# pmac_rx_secure register map
Vendor: Texas Instruments
Registers are 32-bit, read-only, reset 0x0 unless marked. A register's access mark holds for its fields unless they carry their own. Offsets are as the file gives them; [hi:lo] are bit positions; lines under a group give offsets from that group; {n}, {i} and the like mark numbered series; <NAME> marks a mode.

## pmac_rx_secure (part 3 of 3)
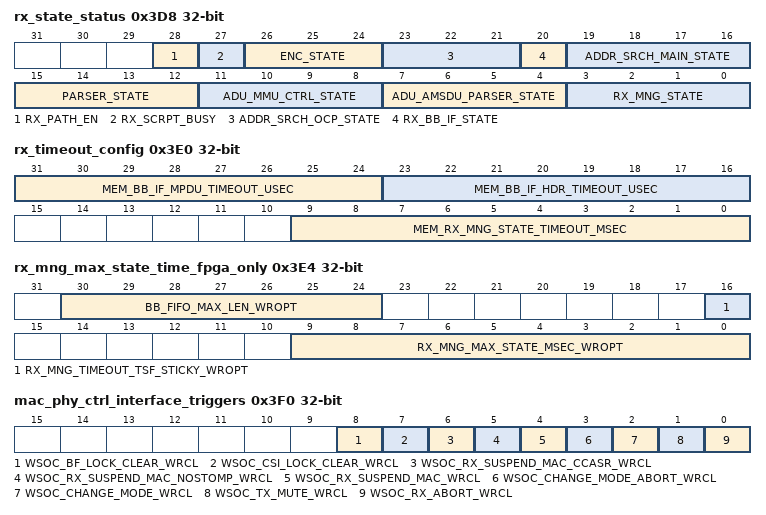
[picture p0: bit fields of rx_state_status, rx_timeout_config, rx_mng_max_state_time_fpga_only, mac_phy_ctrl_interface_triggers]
0x3D8 rx_state_status
  [28] RX_PATH_EN — state of internal rx path enable signal
  [27] RX_SCRPT_BUSY
  [26:24] ENC_STATE — 3'h0 = IDLE 3'h1 = PARSE_HDR_SEC_HDR 3'h2 = WAIT_CMD2 3'h3 = GET_KEY 3'h4 = START_ENGINE 3'h5 = ENGINE_BUSY 3'h6 = OCP_FLUSH 3'h7 = UPDATE_STS
  [23:21] ADDR_SRCH_OCP_STATE — 3'd0 = OCP_IDLE 3'd1 = RD_HASH 3'd2 = WAIT_FOR_RES 3'd3 = RD_1_FIRST 3'd4 = RD_2_FIRST 3'd5 = RD_1_NEXT 3'd6 = RD_2_NEXT 3'd7 = LAST_COMPARE
  [20] RX_BB_IF_STATE
  [19:16] ADDR_SRCH_MAIN_STATE — 3'd0 = IDLE 3'd1 = WAIT_ADDR_1 3'd2 = PROC_ADDR_1 3'd3 = WAIT_ADDR_2 3'd4 = PROC_ADDR_2 3'd5 = WAIT_ADDR_3 3'd6 = PROC_ADDR_3 3'd7 = WAIT_ADDR_4 3'd8 = PROC_ADDR_4 3'd9 = DONE
  [15:12] PARSER_STATE — 3'd0 = IDLE 3'd2 = HEADER 3'd3 = IEID 3'd4 = IELEN 3'd5 = IEINFO 3'd6 = DONE
  [11:8] ADU_MMU_CTRL_STATE — 4'd0 = WAIT_PRE_ALLOC 4'd1 = SET_ALLOC_REQ 4'd2 = WAIT_FOR_ALLOC_IRQ 4'd3 = GET_ALLOC_STATUS 4'd4 = CAPTURE_VIRT_DESC 4'd5 = NEXT_ADDR_READY 4'd6 = WAIT_FOR_LENGTH 4'd7 = SET_REALLOC_REQ 4'd8 = WAIT_FOR_REALLOC_IRQ 4'd9 = GET_REALLOC_STATUS 4'd10 = POP_DESC
  [7:4] ADU_AMSDU_PARSER_STATE — 4'd0 = PARS_IDLE 4'd1 = GET_ADDR1 4'd2 = MPDU_HDR 4'd3 = WAIT4AES 4'd4 = MSDU_SDR 4'd5 = PAYLOAD 4'd6 = FRAME_DONE 4'd7 = GET_ADDR2 4'd8 = DRAIN_SDR 4'd9 = DRAIN_MSDU 4'd10 = DRAIN_MPDU 4'd11 = MPDU_DONE
  [3:0] RX_MNG_STATE — 4'd 0 = IDLE 4'd 1 = WAIT_RX_DATA 4'd 2 = KICK_1 4'd 3 = WAIT_AES_VALID 4'd 4 = WAIT_SCR 4'd 5 = SCR_MAIN_MPDU 4'd 6 = WAIT_AMPDU 4'd 7 = SCR_FINISH_PPDU 4'd 8 = SCR_TYPE_ERROR 4'd 14 = ADU_KICK_1_EMPTY 4'd 15 = SCR_EMPTY_DESCR
0x3DC rx_scrpt_dbg_bus — internal debug bus of rx_scripter selected by mem_rx_scrpt_dbg_sel
0x3E0 rx_timeout_config access per field reset not defined
  [31:24] MEM_BB_IF_MPDU_TIMEOUT_USEC rw — timeout in usec - no data received from phy for too long time, checked during payload
  [23:16] MEM_BB_IF_HDR_TIMEOUT_USEC rw — timeout in usec - no data received from phy for too long time, checked during rx_header
  [9:0] MEM_RX_MNG_STATE_TIMEOUT_MSEC rw — timeout in msec of rx-manager state (except IDLE) is not changed for too long
0x3E4 rx_mng_max_state_time_fpga_only access per field reset not defined
  [30:24] BB_FIFO_MAX_LEN_WROPT rw — max value of bb_fifo length clear by write 0
  [16] RX_MNG_TIMEOUT_TSF_STICKY_WROPT rw — this is a sticky flag set when rx-manager-state-timeout expired, cleard on write 0 used to latch the two TSF registers (RX_MNG_STATE_CHANGE_TSF and RX_MNG_STATE_TIMEOUT_TSF) until this flag is cleared
  [9:0] RX_MNG_MAX_STATE_MSEC_WROPT rw — max value of rx-manager state timeout counter in msec clear by write 0
0x3E8 rx_mng_state_change_tsf_fpga_only
  [31:0] RX_MNG_STATE_CHANGE_TSF — keep value of TSF (usec) at RX-MANAGER state change = same time as timeout-counter-clear for extra debug info, together with RX_MNG_STATE_TIMEOUT_TSF help to estimate the STATE_TIMEOUT timeout[usec] = RX_MNG_STATE_TIMEOUT_TSF - RX_MNG_STATE_CHANGE_TSF (consider 32-bit TSF wraparound) should correlate with MEM_RX_MNG_STATE_TIMEOUT_MSEC[msec]
0x3EC rx_mng_state_timeout_tsf_fpga_only
  [31:0] RX_MNG_STATE_TIMEOUT_TSF — keep value of TSF (usec) at RX-MANAGER state timeout = same time as timeout-counter-expire for extra debug info, together with RX_MNG_STATE_CHANGE_TSF help to estimate the STATE_TIMEOUT timeout[usec] = RX_MNG_STATE_TIMEOUT_TSF - RX_MNG_STATE_CHANGE_TSF (consider 32-bit TSF wraparound) should correlate with MEM_RX_MNG_STATE_TIMEOUT_MSEC[msec]
0x3F0 mac_phy_ctrl_interface_triggers access per field
  [8] WSOC_BF_LOCK_CLEAR_WRCL wo — Pulse from PMAC to PHY indicating the BF information was already consumed, and can be cleared
  [7] WSOC_CSI_LOCK_CLEAR_WRCL wo — Pulse from PMAC to PHY indicating the CSI memory was consumed and can be cleared
  [6] WSOC_RX_SUSPEND_MAC_CCASR_WRCL wo — Suspend-CCA-Spatial-Reuse. Sideband Pulse (valid only when wsoc_rx_suspend_mac = '1').
  [5] WSOC_RX_SUSPEND_MAC_NOSTOMP_WRCL wo — Suspend-without-STOMP. Sideband Pulse (valid only when wsoc_rx_suspend_mac = '1').
  [4] WSOC_RX_SUSPEND_MAC_WRCL wo — Suspend Indication. May come with either of 2 sideband signals (rx_suspend_mac_nostomp , or rx_suspend_mac_ccasr ).
  [3] WSOC_CHANGE_MODE_ABORT_WRCL wo
  [2] WSOC_CHANGE_MODE_WRCL wo
  [1] WSOC_TX_MUTE_WRCL wo
  [0] WSOC_RX_ABORT_WRCL wo
0x3F4 mac_phy_ctrl_interface_config access per field
  [3:0] MEM_PHY_NEXT_MODE_WROPT rw
0x3F8 links_ps_state access per field
  [23:0] LINKS_PS_STATE_VAL_WROPT rw — state of the connected stations PS. bit per link. 1: STA is in PS 0: STA is active
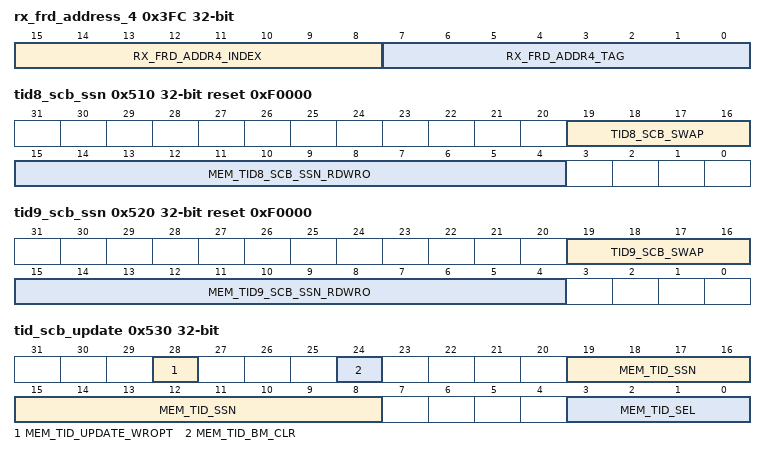
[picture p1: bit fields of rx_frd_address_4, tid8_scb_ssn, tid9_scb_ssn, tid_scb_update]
0x3FC rx_frd_address_4
  [15:8] RX_FRD_ADDR4_INDEX — Results collected from address search mechanism by the the header processing in the PMAC index field value is according to TAG field: TAG = 7 : index = 0..127 descendants TAG = 6 : index = 0..63 links TAG = 5 : index = 0..31 multicast TAG = 4 : index = 0..15 local addr TAG = 3 : index = 0..7 (reserved) TAG = 2 : index = 0..3 (reserved) else : index = 0xFF
  [7:0] RX_FRD_ADDR4_TAG — Results collected from address search mechanism by the the header processing in the PMAC TAG enumeration: 8'd 7 = DESCEND_TAG 8'd 6 = PEER_TAG 8'd 5 = MULTICAST_TAG 8'd 4 = LOCAL_TAG 8'd 3 = RESERVED_3_TAG 8'd 2 = RESERVED_2_TAG 8'd 1 = LOCAL_MESH_TAG 8'd 0 = PARENT_MESH_TAG 8'h FF = ERROR_TAG
{0x400+0x10*i} tid{i}_ba_ssn (i=0..7)
  [15:4] MEM_TID{i}_BA_SSN_RDWRO — TID{i} BA SSN. The user must read all TID{i} BA group registers SSN, BM_LSB and BM_MSB one after the other. SSN register must be read first since it locks the whole group from changing their values. BM_MSB register must be read last to release the lock.
{0x404+0x10*i} tid{i}_ba_bm_lsb (i=0..7)
  [31:0] MEM_TID{i}_BA_BM_LSB_RDWRO — TID{i} BA bitmap 32 LSB. The user must read all TID{i} BA group registers SSN, BM_LSB and BM_MSB one after the other. SSN register must be read first since it locks the whole group from changing their values. BM_MSB register must be read last to release the lock.
{0x408+0x10*i} tid{i}_ba_bm_msb (i=0..7)
  [31:0] MEM_TID{i}_BA_BM_MSB_RDWRO — TID{i} BA bitmap 32 MSB. The user must read all TID{i} BA group registers SSN, BM_LSB and BM_MSB one after the other. SSN register must be read first since it locks the whole group from changing their values. BM_MSB register must be read last to release the lock.
{0x480+0x10*i} tid{i}_scb_ssn access per field (i=0..7)
  [15:4] MEM_TID{i}_SCB_SSN_RDWRO rw — TID{i} SCB SSN
{0x484+0x10*i} tid{i}_scb_bm_lsb rw (i=0..7)
  [31:0] MEM_TID{i}_SCB_BM_LSB_RDWRO — TID{i} SCB bitmap 32 LSB
{0x488+0x10*i} tid{i}_scb_bm_msb rw (i=0..7)
  [31:0] MEM_TID{i}_SCB_BM_MSB_RDWRO — TID{i} SCB bitmap 32 MSB
0x500 tid8_ba_ssn — Scoreboard 8 has two operating modes. The mode is set by scb_mode register. 1. Regular scoreboard in single TID mode (scb_mode=0x0) 2. Dynamic fragmentation scoreboard in multi TID mode (scb_mode=0x1)
  [15:4] MEM_TID8_BA_SSN_RDWRO — TID8 BA SSN. The user must read all TID8 BA group registers SSN, BM_LSB and BM_MSB one after the other. SSN register must be read first since it locks the whole group from changing their values. BM_MSB register must be read last to release the lock.
0x504 tid8_ba_bm_lsb — Scoreboard 8 has two operating modes. The mode is set by scb_mode register. 1. Regular scoreboard in single TID mode (scb_mode=0x0) 2. Dynamic fragmentation scoreboard in multi TID mode (scb_mode=0x1)
  [31:0] MEM_TID8_BA_BM_LSB_RDWRO — TID8 BA bitmap 32 LSB. The user must read all TID8 BA group registers SSN, BM_LSB and BM_MSB one after the other. SSN register must be read first since it locks the whole group from changing their values. BM_MSB register must be read last to release the lock.
0x508 tid8_ba_bm_msb — Scoreboard 8 has two operating modes. The mode is set by scb_mode register. 1. Regular scoreboard in single TID mode (scb_mode=0x0) 2. Dynamic fragmentation scoreboard in multi TID mode (scb_mode=0x1)
  [31:0] MEM_TID8_BA_BM_MSB_RDWRO — TID8 BA bitmap 32 MSB. The user must read all TID8 BA group registers SSN, BM_LSB and BM_MSB one after the other. SSN register must be read first since it locks the whole group from changing their values. BM_MSB register must be read last to release the lock.
0x510 tid8_scb_ssn reset 0xF0000 — Scoreboard 8 has two operating modes. The mode is set by scb_mode register. 1. Regular scoreboard in single TID mode (scb_mode=0x0) 2. Dynamic fragmentation scoreboard in multi TID mode (scb_mode=0x1)
  [19:16] TID8_SCB_SWAP — Indicates which TID holds TID8 SCB for dynamic fragmentation
  [15:4] MEM_TID8_SCB_SSN_RDWRO — TID8 SCB SSN. TID8 is used for dynamic fragmentation
0x514 tid8_scb_bm_lsb — Scoreboard 8 has two operating modes. The mode is set by scb_mode register. 1. Regular scoreboard in single TID mode (scb_mode=0x0) 2. Dynamic fragmentation scoreboard in multi TID mode (scb_mode=0x1)
  [31:0] MEM_TID8_SCB_BM_LSB_RDWRO — TID8 SCB bitmap 32 LSB. TID8 is used for dynamic fragmentation
0x518 tid8_scb_bm_msb — Scoreboard 8 has two operating modes. The mode is set by scb_mode register. 1. Regular scoreboard in single TID mode (scb_mode=0x0) 2. Dynamic fragmentation scoreboard in multi TID mode (scb_mode=0x1)
  [31:0] MEM_TID8_SCB_BM_MSB_RDWRO — TID8 SCB bitmap 32 MSB. TID8 is used for dynamic fragmentation
0x520 tid9_scb_ssn reset 0xF0000
  [19:16] TID9_SCB_SWAP — Indicates which TID holds TID9 SCB for dynamic fragmentation
  [15:4] MEM_TID9_SCB_SSN_RDWRO — TID9 SCB SSN. TID9 is used for dynamic fragmentation
0x524 tid9_scb_bm_lsb
  [31:0] MEM_TID9_SCB_BM_LSB_RDWRO — TID9 SCB bitmap 32 LSB. TID9 is used for dynamic fragmentation
0x528 tid9_scb_bm_msb
  [31:0] MEM_TID9_SCB_BM_MSB_RDWRO — TID9 SCB bitmap 32 MSB. TID9 is used for dynamic fragmentation
0x530 tid_scb_update access per field — In PBAA (Protected block ack agreement) the SW use this register to select and update one TID scoreboard at a time. The SW must check that the MEM_TID_UPDATE_WROPT field value is 0x0 before submitting another request for TID scoreboard update.
  [28] MEM_TID_UPDATE_WROPT rw — Submit update request for the selected TID. The field will be cleared automatically after request completion. 0x0: Request completed 0x1: Submit Request / Request in progress
  [24] MEM_TID_BM_CLR rw — Clear the bitmap of the selected TID (64 bits)
  [19:8] MEM_TID_SSN rw — Set new SSN to the selected TID
  [3:0] MEM_TID_SEL rw — Select which TID scoreboard to update
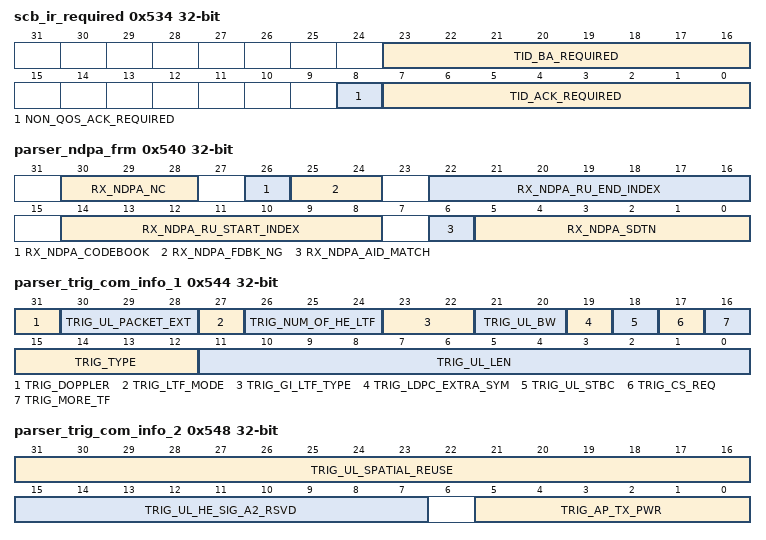
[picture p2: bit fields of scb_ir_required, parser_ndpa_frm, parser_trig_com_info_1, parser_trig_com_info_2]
0x534 scb_ir_required — Hold the status of the Immediate Response (IR) required
  [23:16] TID_BA_REQUIRED — Indicates which TID required BA response. One bit per TID. [0]: TID0 [1]: TID1 [2]: TID2 [3]: TID3 [4]: TID4 [5]: TID5 [6]: TID6 [7]: TID7
  [8] NON_QOS_ACK_REQUIRED — Indicates if non QOS packet required ACK response
  [7:0] TID_ACK_REQUIRED — Indicates which TID required ACK response. One bit per TID. [0]: TID0 [1]: TID1 [2]: TID2 [3]: TID3 [4]: TID4 [5]: TID5 [6]: TID6 [7]: TID7
0x538 scb_bar_ssn_bypass access per field — Bypass BAR SSN checker
  [0] MEM_BAR_SSN_BYPASS rw — Bypass BAR SSN checker STATIC configuration, not expected to change while receiving packets
0x540 parser_ndpa_frm
  [30:28] RX_NDPA_NC, [26] RX_NDPA_CODEBOOK, [25:24] RX_NDPA_FDBK_NG, [22:16] RX_NDPA_RU_END_INDEX, [14:8] RX_NDPA_RU_START_INDEX, [6] RX_NDPA_AID_MATCH, [5:0] RX_NDPA_SDTN
0x544 parser_trig_com_info_1
  [31] TRIG_DOPPLER, [30:28] TRIG_UL_PACKET_EXT, [27] TRIG_LTF_MODE, [26:24] TRIG_NUM_OF_HE_LTF, [23:22] TRIG_GI_LTF_TYPE, [21:20] TRIG_UL_BW, [19] TRIG_LDPC_EXTRA_SYM, [18] TRIG_UL_STBC, [17] TRIG_CS_REQ, [16] TRIG_MORE_TF, [15:12] TRIG_TYPE, [11:0] TRIG_UL_LEN
0x548 parser_trig_com_info_2
  [31:16] TRIG_UL_SPATIAL_REUSE, [15:7] TRIG_UL_HE_SIG_A2_RSVD, [5:0] TRIG_AP_TX_PWR
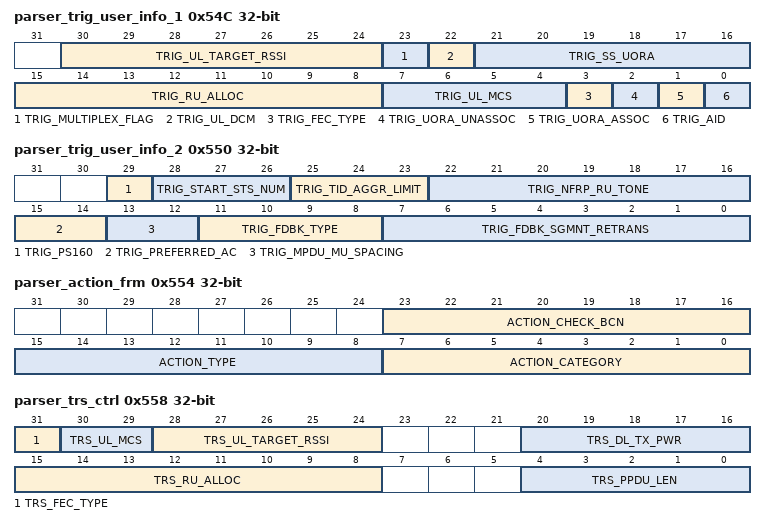
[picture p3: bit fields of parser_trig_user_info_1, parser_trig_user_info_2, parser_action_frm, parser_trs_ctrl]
0x54C parser_trig_user_info_1
  [30:24] TRIG_UL_TARGET_RSSI, [23] TRIG_MULTIPLEX_FLAG, [22] TRIG_UL_DCM, [21:16] TRIG_SS_UORA, [15:8] TRIG_RU_ALLOC, [7:4] TRIG_UL_MCS, [3] TRIG_FEC_TYPE, [2] TRIG_UORA_UNASSOC, [1] TRIG_UORA_ASSOC, [0] TRIG_AID
0x550 parser_trig_user_info_2
  [29] TRIG_PS160, [28:26] TRIG_START_STS_NUM, [25:23] TRIG_TID_AGGR_LIMIT, [22:16] TRIG_NFRP_RU_TONE, [15:14] TRIG_PREFERRED_AC, [13:12] TRIG_MPDU_MU_SPACING, [11:8] TRIG_FDBK_TYPE, [7:0] TRIG_FDBK_SGMNT_RETRANS
0x554 parser_action_frm
  [23:16] ACTION_CHECK_BCN, [15:8] ACTION_TYPE, [7:0] ACTION_CATEGORY
0x558 parser_trs_ctrl
  [31] TRS_FEC_TYPE, [30:29] TRS_UL_MCS, [28:24] TRS_UL_TARGET_RSSI, [20:16] TRS_DL_TX_PWR, [15:8] TRS_RU_ALLOC, [4:0] TRS_PPDU_LEN
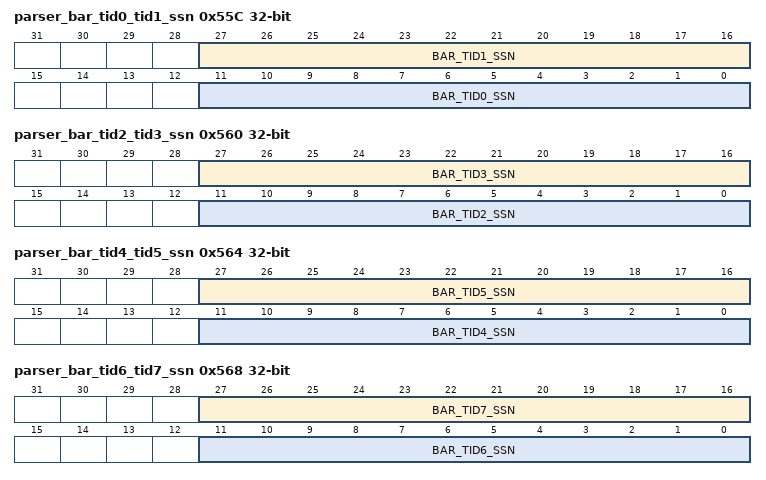
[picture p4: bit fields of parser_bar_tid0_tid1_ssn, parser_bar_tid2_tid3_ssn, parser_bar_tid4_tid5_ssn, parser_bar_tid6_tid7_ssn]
0x55C parser_bar_tid0_tid1_ssn
  [27:16] BAR_TID1_SSN, [11:0] BAR_TID0_SSN
0x560 parser_bar_tid2_tid3_ssn
  [27:16] BAR_TID3_SSN, [11:0] BAR_TID2_SSN
0x564 parser_bar_tid4_tid5_ssn
  [27:16] BAR_TID5_SSN, [11:0] BAR_TID4_SSN
0x568 parser_bar_tid6_tid7_ssn
  [27:16] BAR_TID7_SSN, [11:0] BAR_TID6_SSN
0x56C parser_sec_hdr
  [7:0] SEC_HDR_KEY_ID
0x570 rx_if_bb_rx_last_ovr access per field
  [0] MEM_RX_IF_BB_TIMEOUT_RX_LAST_OVR_EN rw — Enable this bit in order to force rx_last upon rx_bb_if timeout.
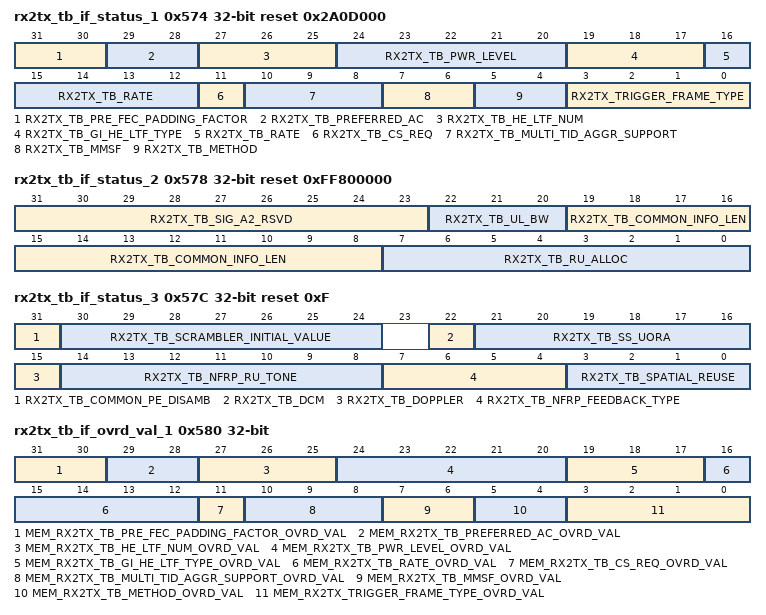
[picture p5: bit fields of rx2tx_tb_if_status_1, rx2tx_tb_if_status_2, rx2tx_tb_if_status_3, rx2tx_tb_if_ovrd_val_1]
0x574 rx2tx_tb_if_status_1 reset 0x2A0D000 — RX2TX TB fields status
  [31:30] RX2TX_TB_PRE_FEC_PADDING_FACTOR, [29:28] RX2TX_TB_PREFERRED_AC, [27:25] RX2TX_TB_HE_LTF_NUM, [24:20] RX2TX_TB_PWR_LEVEL, [19:17] RX2TX_TB_GI_HE_LTF_TYPE, [16:12] RX2TX_TB_RATE, [11] RX2TX_TB_CS_REQ, [10:8] RX2TX_TB_MULTI_TID_AGGR_SUPPORT, [7:6] RX2TX_TB_MMSF, [5:4] RX2TX_TB_METHOD, [3:0] RX2TX_TRIGGER_FRAME_TYPE
0x578 rx2tx_tb_if_status_2 reset 0xFF800000 — RX2TX TB fields status
  [31:23] RX2TX_TB_SIG_A2_RSVD, [22:20] RX2TX_TB_UL_BW, [19:8] RX2TX_TB_COMMON_INFO_LEN, [7:0] RX2TX_TB_RU_ALLOC
0x57C rx2tx_tb_if_status_3 reset 0xF — RX2TX TB fields status
  [31] RX2TX_TB_COMMON_PE_DISAMB, [30:24] RX2TX_TB_SCRAMBLER_INITIAL_VALUE, [22] RX2TX_TB_DCM, [21:16] RX2TX_TB_SS_UORA, [15] RX2TX_TB_DOPPLER, [14:8] RX2TX_TB_NFRP_RU_TONE, [7:4] RX2TX_TB_NFRP_FEEDBACK_TYPE, [3:0] RX2TX_TB_SPATIAL_REUSE
0x580 rx2tx_tb_if_ovrd_val_1 rw — RX2TX TB fields override value
  [31:30] MEM_RX2TX_TB_PRE_FEC_PADDING_FACTOR_OVRD_VAL, [29:28] MEM_RX2TX_TB_PREFERRED_AC_OVRD_VAL, [27:25] MEM_RX2TX_TB_HE_LTF_NUM_OVRD_VAL, [24:20] MEM_RX2TX_TB_PWR_LEVEL_OVRD_VAL, [19:17] MEM_RX2TX_TB_GI_HE_LTF_TYPE_OVRD_VAL, [16:12] MEM_RX2TX_TB_RATE_OVRD_VAL, [11] MEM_RX2TX_TB_CS_REQ_OVRD_VAL, [10:8] MEM_RX2TX_TB_MULTI_TID_AGGR_SUPPORT_OVRD_VAL, [7:6] MEM_RX2TX_TB_MMSF_OVRD_VAL, [5:4] MEM_RX2TX_TB_METHOD_OVRD_VAL, [3:0] MEM_RX2TX_TRIGGER_FRAME_TYPE_OVRD_VAL
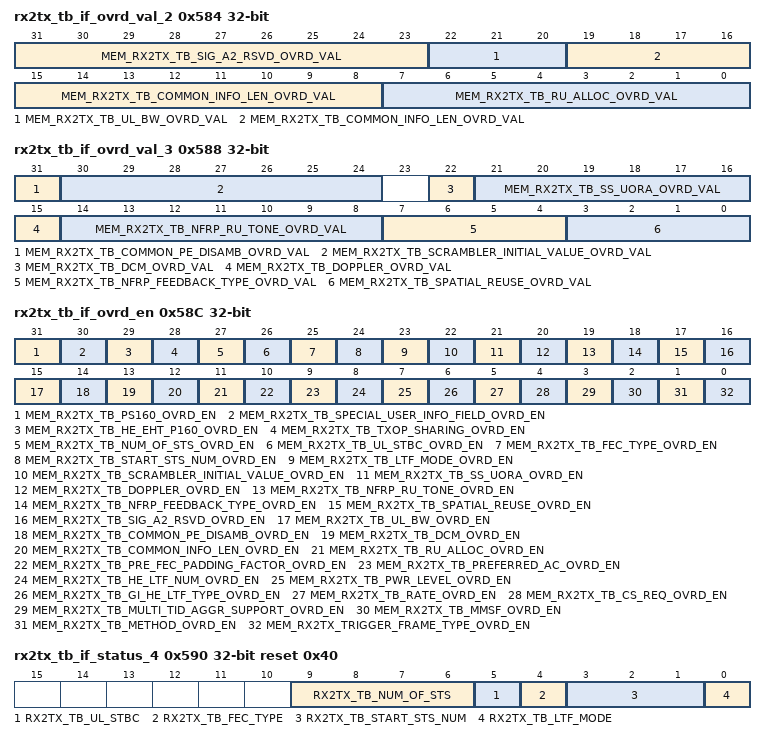
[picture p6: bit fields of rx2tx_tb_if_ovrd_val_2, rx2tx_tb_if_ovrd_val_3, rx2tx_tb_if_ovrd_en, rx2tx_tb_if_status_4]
0x584 rx2tx_tb_if_ovrd_val_2 rw — RX2TX TB fields override value
  [31:23] MEM_RX2TX_TB_SIG_A2_RSVD_OVRD_VAL, [22:20] MEM_RX2TX_TB_UL_BW_OVRD_VAL, [19:8] MEM_RX2TX_TB_COMMON_INFO_LEN_OVRD_VAL, [7:0] MEM_RX2TX_TB_RU_ALLOC_OVRD_VAL
0x588 rx2tx_tb_if_ovrd_val_3 access per field — RX2TX TB fields override value
  [31] MEM_RX2TX_TB_COMMON_PE_DISAMB_OVRD_VAL rw, [30:24] MEM_RX2TX_TB_SCRAMBLER_INITIAL_VALUE_OVRD_VAL rw, [22] MEM_RX2TX_TB_DCM_OVRD_VAL rw, [21:16] MEM_RX2TX_TB_SS_UORA_OVRD_VAL rw, [15] MEM_RX2TX_TB_DOPPLER_OVRD_VAL rw, [14:8] MEM_RX2TX_TB_NFRP_RU_TONE_OVRD_VAL rw, [7:4] MEM_RX2TX_TB_NFRP_FEEDBACK_TYPE_OVRD_VAL rw, [3:0] MEM_RX2TX_TB_SPATIAL_REUSE_OVRD_VAL rw
0x58C rx2tx_tb_if_ovrd_en rw — RX2TX TB fields override enable
  [31] MEM_RX2TX_TB_PS160_OVRD_EN, [30] MEM_RX2TX_TB_SPECIAL_USER_INFO_FIELD_OVRD_EN, [29] MEM_RX2TX_TB_HE_EHT_P160_OVRD_EN, [28] MEM_RX2TX_TB_TXOP_SHARING_OVRD_EN, [27] MEM_RX2TX_TB_NUM_OF_STS_OVRD_EN, [26] MEM_RX2TX_TB_UL_STBC_OVRD_EN, [25] MEM_RX2TX_TB_FEC_TYPE_OVRD_EN, [24] MEM_RX2TX_TB_START_STS_NUM_OVRD_EN, [23] MEM_RX2TX_TB_LTF_MODE_OVRD_EN, [22] MEM_RX2TX_TB_SCRAMBLER_INITIAL_VALUE_OVRD_EN, [21] MEM_RX2TX_TB_SS_UORA_OVRD_EN, [20] MEM_RX2TX_TB_DOPPLER_OVRD_EN, [19] MEM_RX2TX_TB_NFRP_RU_TONE_OVRD_EN, [18] MEM_RX2TX_TB_NFRP_FEEDBACK_TYPE_OVRD_EN, [17] MEM_RX2TX_TB_SPATIAL_REUSE_OVRD_EN, [16] MEM_RX2TX_TB_SIG_A2_RSVD_OVRD_EN, [15] MEM_RX2TX_TB_UL_BW_OVRD_EN, [14] MEM_RX2TX_TB_COMMON_PE_DISAMB_OVRD_EN, [13] MEM_RX2TX_TB_DCM_OVRD_EN, [12] MEM_RX2TX_TB_COMMON_INFO_LEN_OVRD_EN, [11] MEM_RX2TX_TB_RU_ALLOC_OVRD_EN, [10] MEM_RX2TX_TB_PRE_FEC_PADDING_FACTOR_OVRD_EN, [9] MEM_RX2TX_TB_PREFERRED_AC_OVRD_EN, [8] MEM_RX2TX_TB_HE_LTF_NUM_OVRD_EN, [7] MEM_RX2TX_TB_PWR_LEVEL_OVRD_EN, [6] MEM_RX2TX_TB_GI_HE_LTF_TYPE_OVRD_EN, [5] MEM_RX2TX_TB_RATE_OVRD_EN, [4] MEM_RX2TX_TB_CS_REQ_OVRD_EN, [3] MEM_RX2TX_TB_MULTI_TID_AGGR_SUPPORT_OVRD_EN, [2] MEM_RX2TX_TB_MMSF_OVRD_EN, [1] MEM_RX2TX_TB_METHOD_OVRD_EN, [0] MEM_RX2TX_TRIGGER_FRAME_TYPE_OVRD_EN
0x590 rx2tx_tb_if_status_4 reset 0x40 — RX2TX TB fields status
  [9:6] RX2TX_TB_NUM_OF_STS, [5] RX2TX_TB_UL_STBC, [4] RX2TX_TB_FEC_TYPE, [3:1] RX2TX_TB_START_STS_NUM, [0] RX2TX_TB_LTF_MODE
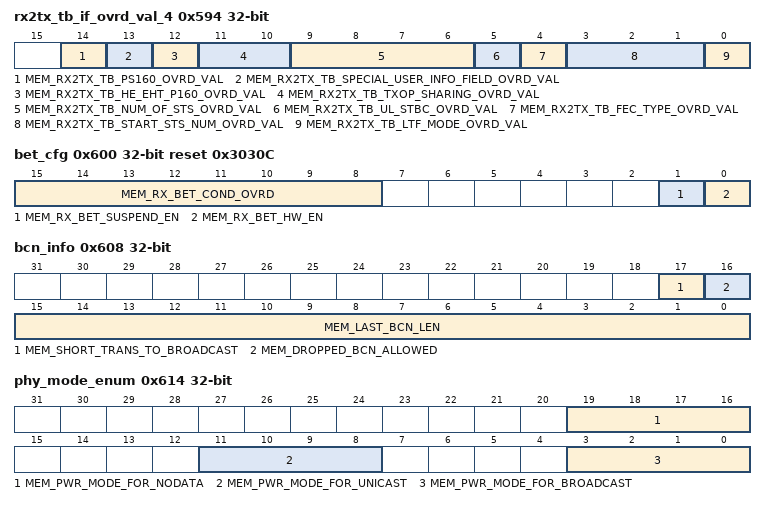
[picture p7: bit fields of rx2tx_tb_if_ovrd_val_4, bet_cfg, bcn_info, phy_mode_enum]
0x594 rx2tx_tb_if_ovrd_val_4 access per field — RX2TX TB fields override value
  [14] MEM_RX2TX_TB_PS160_OVRD_VAL rw, [13] MEM_RX2TX_TB_SPECIAL_USER_INFO_FIELD_OVRD_VAL rw, [12] MEM_RX2TX_TB_HE_EHT_P160_OVRD_VAL rw, [11:10] MEM_RX2TX_TB_TXOP_SHARING_OVRD_VAL rw, [9:6] MEM_RX2TX_TB_NUM_OF_STS_OVRD_VAL rw, [5] MEM_RX2TX_TB_UL_STBC_OVRD_VAL rw, [4] MEM_RX2TX_TB_FEC_TYPE_OVRD_VAL rw, [3:1] MEM_RX2TX_TB_START_STS_NUM_OVRD_VAL rw, [0] MEM_RX2TX_TB_LTF_MODE_OVRD_VAL rw
0x600 bet_cfg access per field reset 0x3030C (reset mask 0xFFFFFFFC) — Beacon Early Termination - Module configuration
  [15:8] MEM_RX_BET_COND_OVRD rw — Override bits to ignore each of the conditions for termination decision: '1' - to override the condition, which means - beacon can be terminated regardless of the specific condition: bit-0 for: Frame is beacon bit-1 for: Frame in our BSS bit-2 for: Beacon Length matches the previous ones bit-3 for: Counter of previous dropped beacons - if reaches a THR number do not terminate bit-4 for: Reasonable timestamp - STA and AP are aligned on TSF
  [1] MEM_RX_BET_SUSPEND_EN rw — Configurable reg to enable BET module to Suspend '1' - Enable (default) '0' - Disable
  [0] MEM_RX_BET_HW_EN rw — Configurable reg to Enable/Disable all BET decisions outputs (Abort/Suspend/Change-Mode) '1' - Enable (default) '0' - Disable
0x604 bet_db_proc_done access per field reset 0x3 — Enable indication from scripter for BET module
  [0] MEM_RX_BET_DB_PROC_DONE rw — Indication that all relevant information for the BET module was downloaded and valid. Default is '1', but if scripter wants to hold the final decision until relevant data is downloaded, it writes '0' to this bit at the beginning of the first script, and when data was downloaded then it writes back '1', which enables the BET module to output the final decisions when ready.
0x608 bcn_info access per field reset not defined — Beacon information for BET conditions
  [17] MEM_SHORT_TRANS_TO_BROADCAST rw — Configurable reg to tell if PHY mode transition is short enough, so broadcast frames can be sent right after beacon reception is completed (SIFS + AIFS). '0' - Abort will be recommended if broadcast change mode is required (to 'RX-Only or Normal) '1' - Complete beacon reception in this case (or suspend if it fits the conditions)
  [16] MEM_DROPPED_BCN_ALLOWED rw — SW recommendation to avoid termination of current beacon (for condition #4 ('mem_rx_bet_cond_ovrd':bit-3)). Change mode or abort (for broadcast change mode) can still take place.
  [15:0] MEM_LAST_BCN_LEN rw — Last beacon length fully delivered to SW (for condition #3 ('mem_rx_bet_cond_ovrd':bit-2)). (beacon length == PLCP length minus the TIM IE that may vary)
0x60C timestamp_thr access per field reset 0x1FC1FC00 — Timestamp Thershold
  [16:5] MEM_TSF_MAX_GAP_BITMASK rw — Bit-Mask configuration to check the difference between expected AP-TSF (mem_expected_bcn_timestamp) and the AP-Timestamp field from the received beacon. This register represents which of the lsb bits to mask, for example If this register is set to 0x007F - it means compare only the 20 msbits and ignore the 12 lsb. In order to save bits when comparing the minimum number of bits to mask will be 5 (meaning resolution is 32uSec). Reg-val Actual mask time resolution [16:5] [31:0] Mask [us] ------- --------- ---------------- 000 0000_001F 32 001 0000_003F 64 003 0000_007F 128 007 0000_00FF 256 00F 0000_01FF 512 01F 0000_03FF 1024 03F 0000_07FF 2048 07F 0000_0FFF 4096 0FF 0000_1FFF 8192 1FF 0000_3FFF 16384 3FF 0000_7FFF 32768 7FF 0000_FFFF 65536 FFF 0001_FFFF 131072 (~130mSec of difference ignore)
0x610 expected_timestamp access per field — Calculated Station Timestamp
  [31:5] MEM_EXPECTED_BCN_TIMESTAMP rw — [31:5] - SW calculated TSF for expected timestamp in the coming beacon - resolution is 32uSec [31:5]
0x614 phy_mode_enum access per field reset not defined — PHY Power Mode Enumeration
  [19:16] MEM_PWR_MODE_FOR_NODATA rw — Configurable reg reflects required pwr-mode for No-Data (Default 'Prepare-to-Sleep')
  [11:8] MEM_PWR_MODE_FOR_UNICAST rw — Configurable reg reflects required pwr-mode for Unicast (Default 'Normal')
  [3:0] MEM_PWR_MODE_FOR_BROADCAST rw — Configurable reg reflects required pwr-mode for Broadcast (Default 'RX-Only')
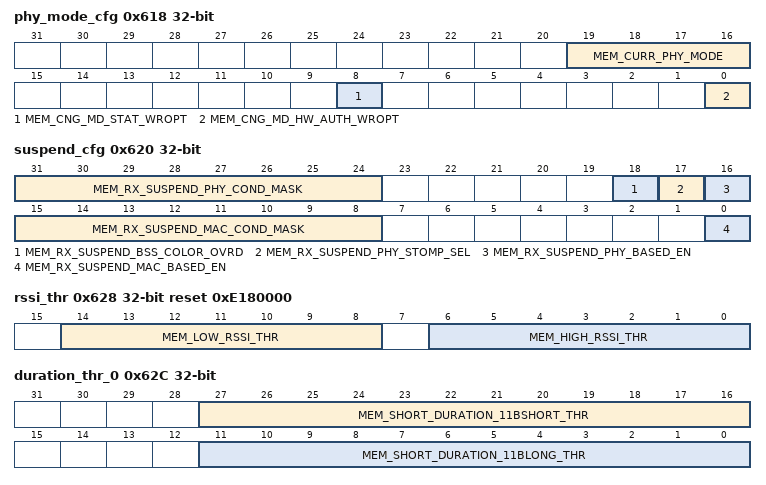
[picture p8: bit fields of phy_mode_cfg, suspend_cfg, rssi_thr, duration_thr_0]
0x618 phy_mode_cfg access per field reset not defined — PMAC authority handshake and current PHY-Mode
  [19:16] MEM_CURR_PHY_MODE rw — SW configuration of current PHY power mode: 0- Normal 1- RX-Only 2- Listen 3- Off 4- LPDS 5- Idle 6- Standby 7- Prepared to sleep
  [8] MEM_CNG_MD_STAT_WROPT rw — Status bit to tell SW if HW issued change-mode request '1' - Change mode command sent by HW, in this case HW also clear 'Authority' bit, so HW can not send another change-mode command
  [0] MEM_CNG_MD_HW_AUTH_WROPT rw — SW gives the 'Authority' to either HW of SW, to issue change-mode request if needed: '0' - Only SW is allowed to change mode '1' - Only HW is allowed to change mode SW may take the 'Authority' back by clearing this bit
0x620 suspend_cfg access per field reset not defined — RX-Suspend - Module configuration
  [31:24] MEM_RX_SUSPEND_PHY_COND_MASK rw — Mask bit for each of the PHY based conditions. '1' - disable this condition, which means, suspend will not be issued for this specific condition: bit-0 for: [HE] - MultiUser downlink that doesn't include us bit-1 for: [HE] - Uplink frame in our BSS bit-2 for: [HE] - Downlink with unsupported rate (bss color match) bit-3 for: [HE] - TB uplink frame in our BSS bit-4 for: [HE] - Unsupported rate (bssid unknown)
  [18] MEM_RX_SUSPEND_BSS_COLOR_OVRD rw — Override bssid match condition for the PHY-based suspension decision
  [17] MEM_RX_SUSPEND_PHY_STOMP_SEL rw — Select if frames suspension based on PHY-Header are W/Stomp ('1') or WO/Stomp ('0'-default)
  [16] MEM_RX_SUSPEND_PHY_BASED_EN rw — Configurable reg to Enable/Disable AX/AC frame Suspension decisions outputs, based on PHY-Header '1' - Enable (default) '0' - Disable
  [15:8] MEM_RX_SUSPEND_MAC_COND_MASK rw — Mask bit for each of the MAC based conditions. '1' - disable this condition, which means, suspend will not be issued for this specific condition: bit-0 for: Frame is not in our BSS bit-1 for: Unicast data not to us bit-2 for: Long data broadcast bit-3 for: Multicast data not to us bit-4 for: [HE] - No more valid data in current aggregation
  [0] MEM_RX_SUSPEND_MAC_BASED_EN rw — Configurable reg to Enable/Disable Frame Suspension decisions outputs, based on MAC-Header: '1' - Enable (default) '0' - Disable
0x624 suspend_db_proc_done access per field reset 0x3 — Enable indication from scripter for Suspend module
  [0] MEM_RX_SUSPEND_DB_PROC_DONE rw — Indication that all relevant information for the SUSPEND module was downloaded and valid. Default is '1', but if scripter wants to hold the final decision until relevant data is downloaded, it writes '0' to this bit at the beginning of the first script, and when data was downloaded then it writes back '1', which enables the BET module to output the final decisions when ready.
0x628 rssi_thr access per field reset 0xE180000 (reset mask 0xFFFF8000) — RSSI Threshold
  [14:8] MEM_LOW_RSSI_THR rw — Configurable Threshold for Low RSSI ('rx_rssi') - (0= -110dBm, 127= 17dBm) Below this threshold RSSI is low - it allows Suspend with Spatial-Reuse
  [6:0] MEM_HIGH_RSSI_THR rw — Configurable Threshold for High RSSI ('rx_rssi') - (0= -110dBm, 127= 17dBm) Above this threshold suspend w/stomp is 'upgraded' to suspend no/stomp
0x62C duration_thr_0 access per field reset not defined — Duration Threshold
  [27:16] MEM_SHORT_DURATION_11BSHORT_THR rw — For 11B-SHORT frame format - Threshold set for short 'rx_duration_id' Some frame should be suspended in case the duration field is not higher than SIFS & ack protection
  [11:0] MEM_SHORT_DURATION_11BLONG_THR rw — For 11B-LONG frame format - Threshold set for short 'rx_duration_id' Some frame should be suspended in case the duration field is not higher than SIFS & ack protection
0x630 duration_thr_1 access per field reset 0x78078 — Duration Threshold
  [11:0] MEM_SHORT_DURATION_NON11B_THR rw — For non-11B frame format (ofdm, 11n, 11ax etc) - Threshold set for short 'rx_duration_id' Some frame should be suspended in case the duration field is not higher than SIFS & ack protection
0x634 bdcst_len_thr access per field reset 0x50050 — Broadcast Length Threshold
  [11:0] MEM_LONG_BDCST_LEN_THR rw — Threshold set for Long Broadcast Length. Suspend may occure on Long data broadcast.
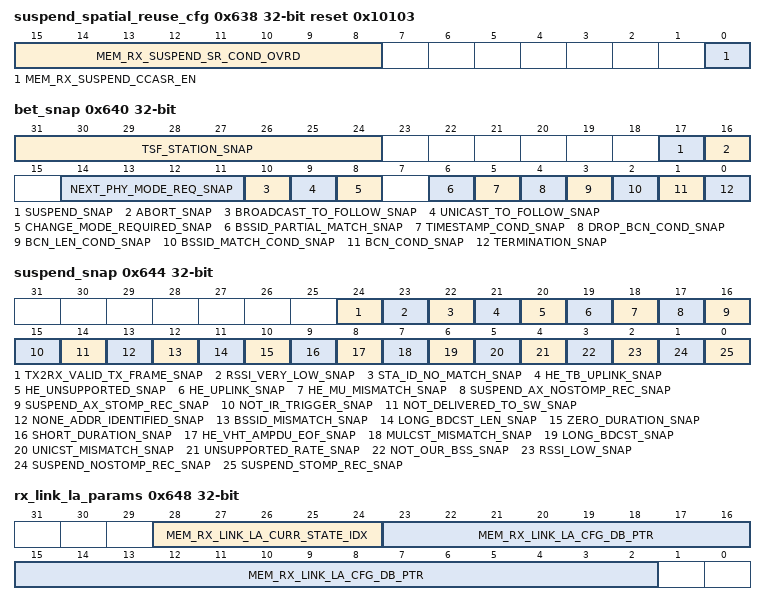
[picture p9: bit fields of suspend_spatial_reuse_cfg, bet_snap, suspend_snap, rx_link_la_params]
0x638 suspend_spatial_reuse_cfg access per field reset 0x10103 — RX-Suspend Spatial-Reuse - Feature configuration
  [15:8] MEM_RX_SUSPEND_SR_COND_OVRD rw — Override bits to ignore each of the conditions for Spatial-Reuse decision: '1' - to override the condition, which means - Spatial-Reuse can be recommended regardless of the specific condition: bit-0 for: There is a frame ready to transmit bit-1 for: Inter BSS - belongs to overlap BSS (not-our-BSS) bit-2 for: MAC address is not identified bit-3 for: Frame will not be forward to SW bit-4 for: Frame does not require Immediate-Resp
  [0] MEM_RX_SUSPEND_CCASR_EN rw — Configurable reg to Enable/Disable Frame Suspension with Spatial-Reuse (SR - CCA clear), based on MAC-Header: '1' - Enable (default) '0' - Disable
0x640 bet_snap — Snapshot of BET module
  [31:24] TSF_STATION_SNAP — Snap condition prior to BET decision - at 'bet_decision_stb' 8 bits of the received Timestamp received from the beacon: Represent bits 5 to 12 - AP-TSF[12:5] (bits 0-4 are masked anyway)
  [17] SUSPEND_SNAP — Snap condition prior to BET decision - at 'bet_decision_stb' Suspend is the BET decision recommendation
  [16] ABORT_SNAP — Snap condition prior to BET decision - at 'bet_decision_stb' Abort is the BET decision recommendation
  [14:11] NEXT_PHY_MODE_REQ_SNAP — Snap condition prior to BET decision - at 'bet_decision_stb' Target PHY-Mode (Unicast, Broadcast or None)
  [10] BROADCAST_TO_FOLLOW_SNAP — Snap condition prior to BET decision - at 'bet_decision_stb' There is a match for broadcast in the TIM element
  [9] UNICAST_TO_FOLLOW_SNAP — Snap condition prior to BET decision - at 'bet_decision_stb' There is a match for unicast in the TIM element
  [8] CHANGE_MODE_REQUIRED_SNAP — Snap condition prior to BET decision - at 'bet_decision_stb' Set if Current-PHY-Mode is different from the required target PHY-Mode, and if SW authorized this change mode in this received beacon frame.
  [6] BSSID_PARTIAL_MATCH_SNAP — Snap condition prior to BET decision - at 'bet_decision_stb' Frame in our BSS (due to 'bssid_partial_match' only. For case of 'bssid_match' see different snap - 'bssid_match_cond_snap')
  [5] TIMESTAMP_COND_SNAP — Snap condition prior to BET decision - at 'bet_decision_stb' reasonable_timestamp - The expected timestamp (configured by SW - 'mem_expected_bcn_timestamp') is in the expected range ('mem_tsf_max_gap_bitmask')
  [4] DROP_BCN_COND_SNAP — Snap condition prior to BET decision - at 'bet_decision_stb' Dropped counter allows to terminate - set by SW
  [3] BCN_LEN_COND_SNAP — Snap condition prior to BET decision - at 'bet_decision_stb' Beacon Length match the previous ones
  [2] BSSID_MATCH_COND_SNAP — Snap condition prior to BET decision - at 'bet_decision_stb' Frame in our BSS (due to 'bssid_match' only. For case of 'bssid_partial_match' see different snap - 'bssid_partial_match_snap')
  [1] BCN_COND_SNAP — Snap condition prior to BET decision - at 'bet_decision_stb' Frame is beacon
  [0] TERMINATION_SNAP — Snap condition prior to BET decision - at 'bet_decision_stb' Decision made on the received beacon, based on the relevant conditions
0x644 suspend_snap — Snapshot of SUSPEND module
  [24] TX2RX_VALID_TX_FRAME_SNAP — Snap condition of Early-Suspend decision - at 'phy_decision_stb' There is a frame ready to transmit (TX) - it allows Suspend with Spatial-Reuse
  [23] RSSI_VERY_LOW_SNAP — Snap condition of Early-Suspend decision - at 'phy_decision_stb' Received RSSI is lower than the configurable THR (rx_rssi < mem_low_rssi_thr (-82dBm)) If this received RSSI crosses this configurable THR - it allows Suspend with Spatial-Reuse
  [22] STA_ID_NO_MATCH_SNAP — Snap condition of Early-Suspend decision - at 'phy_decision_stb' (rx_sta_id_list == 3'b0) ; //(0-STA_ID_LIST_NOT_FOUND)
  [21] HE_TB_UPLINK_SNAP — Snap condition of Early-Suspend decision - at 'phy_decision_stb' TB uplink frame in our BSS
  [20] HE_UNSUPPORTED_SNAP — Snap condition of Early-Suspend decision - at 'phy_decision_stb' Downlink with unsupported rate
  [19] HE_UPLINK_SNAP — Snap condition of Early-Suspend decision - at 'phy_decision_stb' Uplink frame in our BSS
  [18] HE_MU_MISMATCH_SNAP — Snap condition of Early-Suspend decision - at 'phy_decision_stb' MultiUser downlink that doesn't include us
  [17] SUSPEND_AX_NOSTOMP_REC_SNAP — Snap condition of Early-Suspend decision - at 'phy_decision_stb' Recommendation of (AX-)Suspend, based on 'he_mu_mismatch', 'he_uplink', 'he_unsupported' and 'he_tb_uplink'
  [16] SUSPEND_AX_STOMP_REC_SNAP — Snap condition of Early-Suspend decision - at 'phy_decision_stb' Recommendation of Suspend (W/Stomp) based on 'not_our_bss' and 'unsupported_rate'
  [15] NOT_IR_TRIGGER_SNAP — Snap condition of Late-Suspend decision - at 'mac_decision_stb' Frame does not requires immediate response - it allows Suspend with Spatial-Reuse
  [14] NOT_DELIVERED_TO_SW_SNAP — Snap condition of Late-Suspend decision - at 'mac_decision_stb' Frame is not going to be forward to SW - it allows Suspend with Spatial-Reuse
  [13] NONE_ADDR_IDENTIFIED_SNAP — Snap condition of Late-Suspend decision - at 'mac_decision_stb' None of the MAC addresses is identified (Not-addr1|2|3|4_match) - it allows Suspend with Spatial-Reuse
  [12] BSSID_MISMATCH_SNAP — Snap condition of Late-Suspend decision - at 'mac_decision_stb' There is a bssid field, but it does not belong to us - it allows Suspend with Spatial-Reuse
  [11] LONG_BDCST_LEN_SNAP — Snap condition of Late-Suspend decision - at 'mac_decision_stb' (plcp_length > {4'b0 ,mem_long_bdcst_len_thr}) - for Broadcast frames that are not short
  [10] ZERO_DURATION_SNAP — Snap condition of Late-Suspend decision - at 'mac_decision_stb' (rx_duration_id == 16'b0)
  [9] SHORT_DURATION_SNAP — Snap condition of Late-Suspend decision - at 'mac_decision_stb' (rx_duration_id < mem_short_duration_thr)
  [8] HE_VHT_AMPDU_EOF_SNAP — Snap condition of Late-Suspend decision - at 'mac_decision_stb' No more valid data in current aggregation (padding)
  [7] MULCST_MISMATCH_SNAP — Snap condition of Late-Suspend decision - at 'mac_decision_stb' Multicast data not to us
  [6] LONG_BDCST_SNAP — Snap condition of Late-Suspend decision - at 'mac_decision_stb' Long data broadcast
  [5] UNICST_MISMATCH_SNAP — Snap condition of Late-Suspend decision - at 'mac_decision_stb' Unicast data not to us
  [4] UNSUPPORTED_RATE_SNAP — Snap condition of Late-Suspend decision - at 'mac_decision_stb' Unsupported rate (From PHY Header) - BSSID unknown
  [3] NOT_OUR_BSS_SNAP — Snap condition of Late-Suspend decision - at 'mac_decision_stb' Frame is not in our BSS
  [2] RSSI_LOW_SNAP — Snap condition of Late-Suspend decision - at 'mac_decision_stb' Received RSSI is lower than the config THR (rx_rssi < mem_high_rssi_thr) If this received RSSI crosses this configurable THR, it upgrades 'suspend W/stomp' to 'suspend WO/stomp'
  [1] SUSPEND_NOSTOMP_REC_SNAP — Snap condition of Late-Suspend decision - at 'mac_decision_stb' Recommendation of Suspend (WO/Stomp) based on 'unicst_mismatch' , 'long_bdcst', 'mulcst_mismatch' and 'he_vht_ampdu_eof'
  [0] SUSPEND_STOMP_REC_SNAP — Snap condition of Late-Suspend decision - at 'mac_decision_stb' Recommendation of Suspend (W/Stomp) based on 'not_our_bss' and 'unsupported_rate'
0x648 rx_link_la_params access per field
  [28:24] MEM_RX_LINK_LA_CURR_STATE_IDX rw — Holds the current state the link is at.
  [23:2] MEM_RX_LINK_LA_CFG_DB_PTR rw — Hold the pointer for LA coniguration DB.
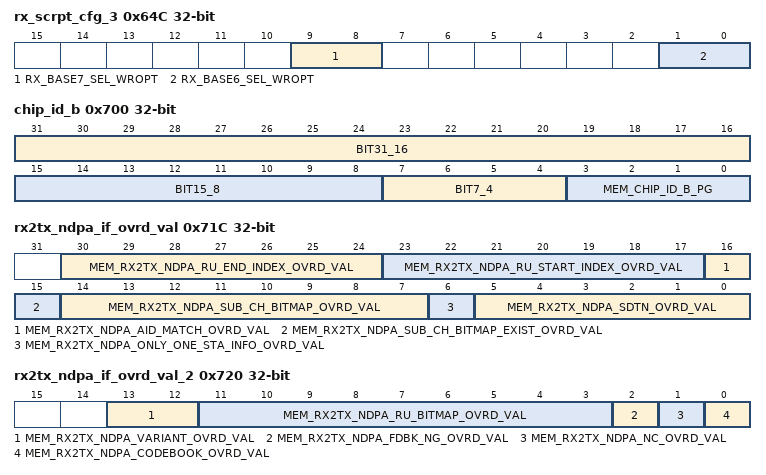
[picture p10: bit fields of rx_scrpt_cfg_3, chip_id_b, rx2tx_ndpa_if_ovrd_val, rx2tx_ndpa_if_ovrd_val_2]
0x64C rx_scrpt_cfg_3 access per field reset not defined
  [9:8] RX_BASE7_SEL_WROPT rw, [1:0] RX_BASE6_SEL_WROPT rw
0x650 rx_scrpt_base7_offset access per field — Base7 offset is added to Base7 in TX Scripter wrapper. Increment and decrement logic was implemented to ease Scripter update, Byte Enable - 2'b01 : (+) Increment previous value (with immediate value) Byte Enable - 2'b10 : (-) Decrement previous value (with immediate value) Byte Enable - 2'b11 : (ld) Initilize previous value (with immediate value)
  [15:0] RX_SCRPT_BASE7_OFFSET_WROPT rw — Immedite value written by scripter can be only one byte width [7:0].
0x654 rx_la_rx_notify_req access per field
  [0] RX_LA_RX_NOTIFY_REQ_WRCL wo
0x700 chip_id_b access per field reset not defined — Chip ID (CHIP_ID_B) Register
  [31:16] BIT31_16 ro — CHIP_ID: Osprey: 16'h1010 OLD: 07 - 1251 0403 - 1273 (TRIO) 0503 - quattro
  [15:8] BIT15_8 ro — FPGA ID
  [7:4] BIT7_4 ro — PG: 00 - PG0.0 01 - PG1.0 11 - PG2.0 12 - PG1.2 13 - PG1.3
  [3:0] MEM_CHIP_ID_B_PG rw
0x704 scr_pad0 rw — Scratch Pad Registers
  [31:0] MEM_SCR_PAD0_WROPT — Scratch Pad Register. These registers provide general_purpose scratch pad register space for eCPU and host access.
0x708 scr_pad0_clr wo — Scratch Pad Clear Register
  [31:0] SCR_PAD0_CLR_WRCL — Scratch Pad0 Clear. Bit-wise CLEAR for Scratch Pad register.
0x70C scr_pad0_set wo — Scratch Pad 4 Set Register
  [31:0] SCR_PAD0_SET_WRCL — Scratch Pad0 Set. Bit-wise SET for Scratch Pad Register.
0x710 links_ps_state_set access per field reset not defined
  [23:0] LINKS_PS_STATE_SET_WRCL wo — Bit-wise SET for LINK_PS_STATE Register (links_ps_state_val_wropt[23:0] register)
0x714 links_ps_state_clr access per field reset not defined — LINKS_PS_STATE - CLEAR register
  [23:0] LINKS_PS_STATE_CLR_WRCL wo — Bit-wise CLEAR for LINK_PS_STATE Register (links_ps_state_val_wropt[23:0] register)
0x718 rx_if_bb_tx_frm_protect_en access per field
  [0] MEM_RX_IF_BB_TX_FRM_PROTECT_EN rw — Enable this bit in order to mask rx_header when tx_frm is high (MAC TX is using AES). Note, protection is only for the case RX starts in the middle of tx_frm (not tx_frm rise in middle of RX).
0x71C rx2tx_ndpa_if_ovrd_val access per field — RX2TX TB fields override value
  [30:24] MEM_RX2TX_NDPA_RU_END_INDEX_OVRD_VAL rw, [23:17] MEM_RX2TX_NDPA_RU_START_INDEX_OVRD_VAL rw, [16] MEM_RX2TX_NDPA_AID_MATCH_OVRD_VAL rw, [15] MEM_RX2TX_NDPA_SUB_CH_BITMAP_EXIST_OVRD_VAL rw, [14:7] MEM_RX2TX_NDPA_SUB_CH_BITMAP_OVRD_VAL rw, [6] MEM_RX2TX_NDPA_ONLY_ONE_STA_INFO_OVRD_VAL rw, [5:0] MEM_RX2TX_NDPA_SDTN_OVRD_VAL rw
0x720 rx2tx_ndpa_if_ovrd_val_2 access per field — RX2TX TB fields override value
  [13:12] MEM_RX2TX_NDPA_VARIANT_OVRD_VAL rw — Override value for ndpa_variant
  [11:3] MEM_RX2TX_NDPA_RU_BITMAP_OVRD_VAL rw
  [2] MEM_RX2TX_NDPA_FDBK_NG_OVRD_VAL rw
  [1] MEM_RX2TX_NDPA_NC_OVRD_VAL rw
  [0] MEM_RX2TX_NDPA_CODEBOOK_OVRD_VAL rw
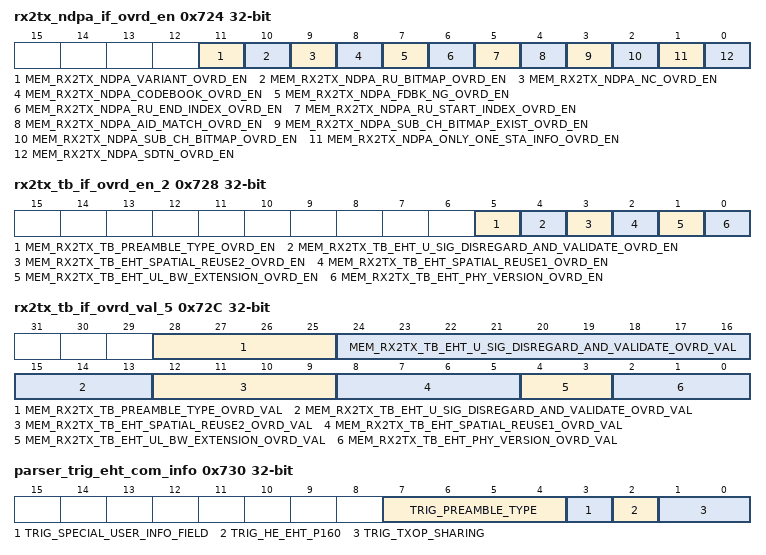
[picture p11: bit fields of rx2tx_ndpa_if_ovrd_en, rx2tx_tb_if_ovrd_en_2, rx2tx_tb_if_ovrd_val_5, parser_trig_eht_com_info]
0x724 rx2tx_ndpa_if_ovrd_en access per field — RX2TX TB fields override enable
  [11] MEM_RX2TX_NDPA_VARIANT_OVRD_EN rw — Overwrite ndpa_variant
  [10] MEM_RX2TX_NDPA_RU_BITMAP_OVRD_EN rw
  [9] MEM_RX2TX_NDPA_NC_OVRD_EN rw
  [8] MEM_RX2TX_NDPA_CODEBOOK_OVRD_EN rw
  [7] MEM_RX2TX_NDPA_FDBK_NG_OVRD_EN rw
  [6] MEM_RX2TX_NDPA_RU_END_INDEX_OVRD_EN rw
  [5] MEM_RX2TX_NDPA_RU_START_INDEX_OVRD_EN rw
  [4] MEM_RX2TX_NDPA_AID_MATCH_OVRD_EN rw
  [3] MEM_RX2TX_NDPA_SUB_CH_BITMAP_EXIST_OVRD_EN rw
  [2] MEM_RX2TX_NDPA_SUB_CH_BITMAP_OVRD_EN rw
  [1] MEM_RX2TX_NDPA_ONLY_ONE_STA_INFO_OVRD_EN rw
  [0] MEM_RX2TX_NDPA_SDTN_OVRD_EN rw
0x728 rx2tx_tb_if_ovrd_en_2 access per field — RX2TX TB fields override enable
  [5] MEM_RX2TX_TB_PREAMBLE_TYPE_OVRD_EN rw, [4] MEM_RX2TX_TB_EHT_U_SIG_DISREGARD_AND_VALIDATE_OVRD_EN rw, [3] MEM_RX2TX_TB_EHT_SPATIAL_REUSE2_OVRD_EN rw, [2] MEM_RX2TX_TB_EHT_SPATIAL_REUSE1_OVRD_EN rw, [1] MEM_RX2TX_TB_EHT_UL_BW_EXTENSION_OVRD_EN rw, [0] MEM_RX2TX_TB_EHT_PHY_VERSION_OVRD_EN rw
0x72C rx2tx_tb_if_ovrd_val_5 access per field — RX2TX TB fields override value
  [28:25] MEM_RX2TX_TB_PREAMBLE_TYPE_OVRD_VAL rw, [24:13] MEM_RX2TX_TB_EHT_U_SIG_DISREGARD_AND_VALIDATE_OVRD_VAL rw, [12:9] MEM_RX2TX_TB_EHT_SPATIAL_REUSE2_OVRD_VAL rw, [8:5] MEM_RX2TX_TB_EHT_SPATIAL_REUSE1_OVRD_VAL rw, [4:3] MEM_RX2TX_TB_EHT_UL_BW_EXTENSION_OVRD_VAL rw, [2:0] MEM_RX2TX_TB_EHT_PHY_VERSION_OVRD_VAL rw
0x730 parser_trig_eht_com_info
  [7:4] TRIG_PREAMBLE_TYPE, [3] TRIG_SPECIAL_USER_INFO_FIELD, [2] TRIG_HE_EHT_P160, [1:0] TRIG_TXOP_SHARING
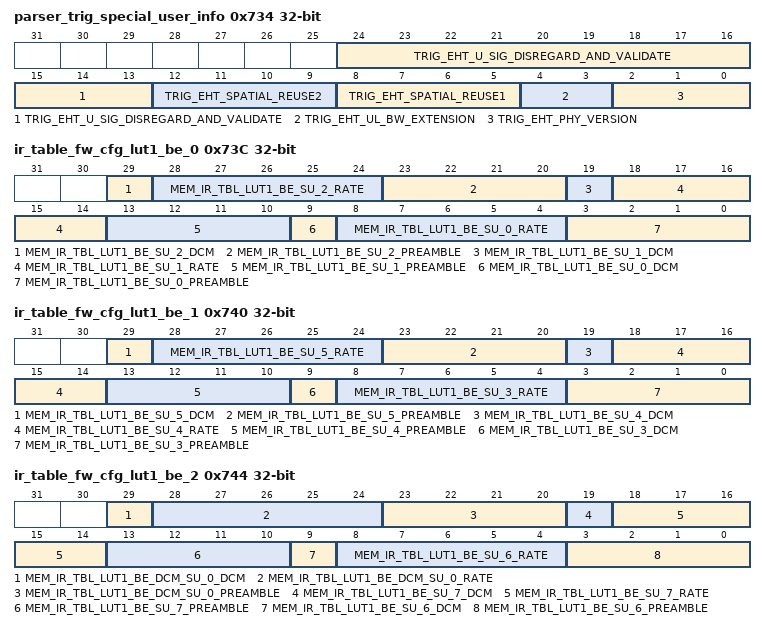
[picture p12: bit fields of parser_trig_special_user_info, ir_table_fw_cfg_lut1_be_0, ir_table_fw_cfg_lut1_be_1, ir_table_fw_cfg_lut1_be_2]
0x734 parser_trig_special_user_info
  [24:13] TRIG_EHT_U_SIG_DISREGARD_AND_VALIDATE, [12:9] TRIG_EHT_SPATIAL_REUSE2, [8:5] TRIG_EHT_SPATIAL_REUSE1, [4:3] TRIG_EHT_UL_BW_EXTENSION, [2:0] TRIG_EHT_PHY_VERSION
0x738 parser_valid_exist_status_2
  [0] TRIG_SPECIAL_USER_INFO_VALID
0x73C ir_table_fw_cfg_lut1_be_0 access per field — LUT1 - AX - for HE frame response. Configuration for the HE imm-resp Output set (Preamble, Rate, DCM). Param in: AX-SU (MCS0-MCS2)
  [29] MEM_IR_TBL_LUT1_BE_SU_2_DCM rw — Configured DCM mode of the AX response frame for MCS2 (19.5Mbps).
  [28:24] MEM_IR_TBL_LUT1_BE_SU_2_RATE rw — Configured RATE of the AX response frame for MCS2 (19.5Mbps).
  [23:20] MEM_IR_TBL_LUT1_BE_SU_2_PREAMBLE rw — Configured PREAMBLE of the AX response frame for MCS2 (19.5Mbps).
  [19] MEM_IR_TBL_LUT1_BE_SU_1_DCM rw — Configured DCM mode of the AX response frame for MCS1 (13Mbps).
  [18:14] MEM_IR_TBL_LUT1_BE_SU_1_RATE rw — Configured RATE of the AX response frame for MCS1 (13Mbps).
  [13:10] MEM_IR_TBL_LUT1_BE_SU_1_PREAMBLE rw — Configured PREAMBLE of the AX response frame for MCS1 (13Mbps).
  [9] MEM_IR_TBL_LUT1_BE_SU_0_DCM rw — Configured DCM mode of the AX response frame for MCS0 (6.5Mbps).
  [8:4] MEM_IR_TBL_LUT1_BE_SU_0_RATE rw — Configured RATE of the AX response frame for MCS0 (6.5Mbps).
  [3:0] MEM_IR_TBL_LUT1_BE_SU_0_PREAMBLE rw — Configured PREAMBLE of the AX response frame for MCS0 (6.5Mbps).
0x740 ir_table_fw_cfg_lut1_be_1 access per field — LUT1 - AX - for HE frame response. Configuration for the HE imm-resp Output set (Preamble, Rate, DCM). Param in: AX-SU (MCS0-MCS2)
  [29] MEM_IR_TBL_LUT1_BE_SU_5_DCM rw — Configured DCM mode of the AX response frame for MCS2 (19.5Mbps).
  [28:24] MEM_IR_TBL_LUT1_BE_SU_5_RATE rw — Configured RATE of the AX response frame for MCS2 (19.5Mbps).
  [23:20] MEM_IR_TBL_LUT1_BE_SU_5_PREAMBLE rw — Configured PREAMBLE of the AX response frame for MCS2 (19.5Mbps).
  [19] MEM_IR_TBL_LUT1_BE_SU_4_DCM rw — Configured DCM mode of the AX response frame for MCS1 (13Mbps).
  [18:14] MEM_IR_TBL_LUT1_BE_SU_4_RATE rw — Configured RATE of the AX response frame for MCS1 (13Mbps).
  [13:10] MEM_IR_TBL_LUT1_BE_SU_4_PREAMBLE rw — Configured PREAMBLE of the AX response frame for MCS1 (13Mbps).
  [9] MEM_IR_TBL_LUT1_BE_SU_3_DCM rw — Configured DCM mode of the AX response frame for MCS0 (6.5Mbps).
  [8:4] MEM_IR_TBL_LUT1_BE_SU_3_RATE rw — Configured RATE of the AX response frame for MCS0 (6.5Mbps).
  [3:0] MEM_IR_TBL_LUT1_BE_SU_3_PREAMBLE rw — Configured PREAMBLE of the AX response frame for MCS0 (6.5Mbps).
0x744 ir_table_fw_cfg_lut1_be_2 access per field — LUT1 - AX - for HE frame response. Configuration for the HE imm-resp Output set (Preamble, Rate, DCM). Param in: AX-SU (MCS0-MCS2)
  [29] MEM_IR_TBL_LUT1_BE_DCM_SU_0_DCM rw — Configured DCM mode of the AX response frame for MCS2 (19.5Mbps).
  [28:24] MEM_IR_TBL_LUT1_BE_DCM_SU_0_RATE rw — Configured RATE of the AX response frame for MCS2 (19.5Mbps).
  [23:20] MEM_IR_TBL_LUT1_BE_DCM_SU_0_PREAMBLE rw — Configured PREAMBLE of the AX response frame for MCS2 (19.5Mbps).
  [19] MEM_IR_TBL_LUT1_BE_SU_7_DCM rw — Configured DCM mode of the AX response frame for MCS1 (13Mbps).
  [18:14] MEM_IR_TBL_LUT1_BE_SU_7_RATE rw — Configured RATE of the AX response frame for MCS1 (13Mbps).
  [13:10] MEM_IR_TBL_LUT1_BE_SU_7_PREAMBLE rw — Configured PREAMBLE of the AX response frame for MCS1 (13Mbps).
  [9] MEM_IR_TBL_LUT1_BE_SU_6_DCM rw — Configured DCM mode of the AX response frame for MCS0 (6.5Mbps).
  [8:4] MEM_IR_TBL_LUT1_BE_SU_6_RATE rw — Configured RATE of the AX response frame for MCS0 (6.5Mbps).
  [3:0] MEM_IR_TBL_LUT1_BE_SU_6_PREAMBLE rw — Configured PREAMBLE of the AX response frame for MCS0 (6.5Mbps).
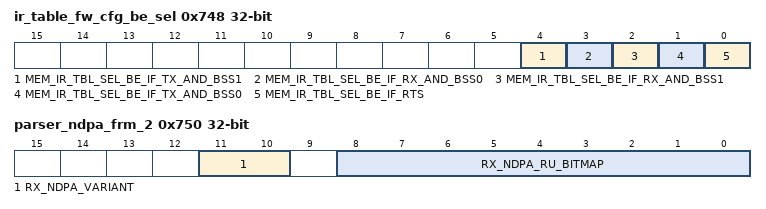
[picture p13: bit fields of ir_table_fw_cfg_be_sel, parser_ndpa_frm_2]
0x748 ir_table_fw_cfg_be_sel access per field — Configuration of immidiate response AX table
  [4] MEM_IR_TBL_SEL_BE_IF_TX_AND_BSS1 rw — Select AX Table i: 1. Client = PMAC-TX 2. BSSID Role Index = 1
  [3] MEM_IR_TBL_SEL_BE_IF_RX_AND_BSS0 rw — Select AX Table i: 1. Client = PMAC-TX 2. BSSID Role Index = 0
  [2] MEM_IR_TBL_SEL_BE_IF_RX_AND_BSS1 rw — Select AX Table i: 1. Client = PMAC-RX 2. BSSID Role Index = 1
  [1] MEM_IR_TBL_SEL_BE_IF_TX_AND_BSS0 rw — Select AX Table i: 1. Client = PMAC-TX 2. BSSID Role Index = 0
  [0] MEM_IR_TBL_SEL_BE_IF_RTS rw — Select AX Table if: Frame Type: Control RTS
0x74C rx_csi_info access per field — Configuration of immidiate response AX table
  [7:0] MEM_RX_CSI_INFO rw — Will be written by PHY FW upon CSI calculation, to indicate current frame got CSI information. Cleared by PHY FW for every new RX packet
0x750 parser_ndpa_frm_2
  [11:10] RX_NDPA_VARIANT, [8:0] RX_NDPA_RU_BITMAP
